AUTOSAR XML (schema 4-3-0)
package /APS_Interface_ARPkg
  client server interface IF_HALIN_APS
    5 x operation:
      CSOP_ApsGetData
        22 x arg, all with direction=OUT, server-argument-impl-policy=USE-ARGUMENT-TYPE:
          u8_GetAPS_Progress_PCT: type=uint8
          u8_GetAPS_RQ_Display: type=uint8
          u8_GetAPS_SW_Ver: type=uint8
          u8_GetAPS_HW_Ver: type=uint8
          u8_GetAPS_ExitCondition: type=uint8
          f32_GetAPS_Angle_Target: type=float32
          u8_GetAPS_Sta_System: type=uint8
          u8_GetAPS_V_Rq_EPAS_Ctrl: type=uint8
          u8_GetAPS_Rq_EPAS_Ctrl: type=uint8
          u8_GetAPS_Req: type=uint8
          f32_GetAPS_DecReq: type=float32
          u8_GetAPS_DecReq_A: type=uint8
          f32_GetAPS_SpeedCmd: type=float32
          u8_GetAPS_ShftPosnReq: type=uint8
          u8_GetAPS_VMC_Req_A: type=uint8
          u8_GetCAAS_Sta: type=uint8
          u8_GetCAAS_VMC_Req_A: type=uint8
          u8_GetAPS_PwrReq_cmd: type=uint8
          u8_GetRAPS_BCM_LockReq_Cmd: type=uint8
          u8_GetRAPS_BCM_Lamp_Cmd: type=uint8
          u8_GetRAPS_ErrWarn_Sta: type=uint8
          u8_GetRAPS_ErrLv1_flg: type=uint8
      CSOP_ApsGetDist
        arg u8Array8_PasInDist: type=u8_PASArray8_type, direction=OUT, server-argument-impl-policy=USE-ARGUMENT-TYPE
        arg u16Array4_ApsInDist: type=u16_APSArray4_type, direction=OUT, server-argument-impl-policy=USE-ARGUMENT-TYPE
      CSOP_ApsGetDistLevel
        arg u8Array8_ApsInLevel: type=u8_APSLevelArray8_type, direction=OUT, server-argument-impl-policy=USE-ARGUMENT-TYPE
      CSOP_ApsGetOtherStatus
        4 x arg, all with type=uint8, direction=OUT, server-argument-impl-policy=USE-ARGUMENT-TYPE:
          u8_ApsInPASChime
          u8_ApsInSensorLayout
          u8_ApsInSysFailSta
          u8_ApsInSysMode
      CSOP_ApsGetUssSta
        arg u8Array12_ApsInUssSta: type=u8_USSArray12_type, direction=OUT, server-argument-impl-policy=USE-ARGUMENT-TYPE
  client server interface IF_HALOUT_APS
    operation CSOP_ApsOutput
      6 x arg, all with direction=IN, server-argument-impl-policy=USE-ARGUMENT-TYPE:
        f32_ApsOutVehSpdSig: type=float32
        u8_ApsOutGearPosnSig: type=uint8
        u8_ApsOutSetFrSensorOnCmd: type=uint8
        u8_ApsOutSetVehSpdTOCmd: type=uint8
        u8_ApsOutSetFrSensorSwTOCmd: type=uint8
        u8_ApsOutSendChrgPlugSta: type=uint8
    operation CSOP_ApsSetData
      83 x arg, all with direction=IN, server-argument-impl-policy=USE-ARGUMENT-TYPE:
        u8_SetPwrSta: type=uint8
        f32_SetBrkPedalPos: type=float32
        f32_SetActAPSPosn: type=float32
        f32_SetLF_RawWhlSpeed: type=float32
        f32_SetRF_RawWhlSpeed: type=float32
        f32_SetLR_RawWhlSpeed: type=float32
        f32_SetRR_RawWhlSpeed: type=float32
        u8_SetLF_RawWhlSpeed_V: type=uint8
        u8_SetRF_RawWhlSpeed_V: type=uint8
        u8_SetLR_RawWhlSpeed_V: type=uint8
        u8_SetRR_RawWhlSpeed_V: type=uint8
        u8_SetLF_WhlRotDir: type=uint8
        u8_SetRF_WhlRotDir: type=uint8
        u8_SetLR_WhlRotDir: type=uint8
        u8_SetRR_WhlRotDir: type=uint8
        u8_SetLF_PulseCount_V: type=uint8
        u8_SetRF_PulseCount_V: type=uint8
        u8_SetLR_PulseCount_V: type=uint8
        u8_SetRR_PulseCount_V: type=uint8
        s16_SetLF_PulseCount: type=sint16
        s16_SetRF_PulseCount: type=sint16
        s16_SetLR_PulseCount: type=sint16
        s16_SetRR_PulseCount: type=sint16
        u8_SetAPS_Active: type=uint8
        u8_SetAPS_CtrlAvail: type=uint8
        u8_SetShifter_Handle_Cmd: type=uint8
        u8_SetDriIntend: type=uint8
        u8_SetEPS_AOI_Control: type=uint8
        f32_SetSAS_Angle: type=float32
        f32_SetSAS_Speed: type=float32
        u8_SetSAS_Speed_Valid: type=uint8
        u8_SetSAS_CAL: type=uint8
        u8_SetSAS_OK: type=uint8
        f32_SetGRADE: type=float32
        f32_SetYawRate: type=float32
        f32_SetLatAccel: type=float32
        f32_SetLongAccel: type=float32
        f32_SetMCPressure: type=float32
        u8_SetYawRate_V: type=uint8
        u8_SetLatAccel_V: type=uint8
        u8_SetLongAccel_V: type=uint8
        u8_SetMCPressure_V: type=uint8
        u8_SetBrkSw_Sta: type=uint8
        u8_SetBrkSw_V: type=uint8
        u8_SetESC_Standstill: type=uint8
        u8_SetESC_APS_Sta: type=uint8
        u8_SetEPBExtReleaseAvail: type=uint8
        u8_SetEPBExtApplyAvail: type=uint8
        u8_SetEPBErrSta: type=uint8
        u8_SetEPBSta: type=uint8
        u8_SetAllDoorSW: type=uint8
        u8_SetHoodSW: type=uint8
        u8_SetTailgate_SW: type=uint8
        u8_SetAVM_parking_cancel: type=uint8
        u8_SetAVM_parking_excute: type=uint8
        u8_SetAVM_Parking_mode: type=uint8
        u8_SetAVM_Err_STA: type=uint8
        u8_SetIVI_Status: type=uint8
        u8_SetCAAS_Sw: type=uint8
        u8_SetIVI_Screen: type=uint8
        u8_SetCAAS_CtrlAvail: type=uint8
        u8_SetABS_Active: type=uint8
        u8_SetTCS_Active: type=uint8
        u8_SetDriverSeatBeltCmd: type=uint8
        u8_SetDrDoorSW: type=uint8
        u8_SetPsDoorSW: type=uint8
        u8_SetRLDoorSW: type=uint8
        u8_SetRRDoorSW: type=uint8
        u8_SetRFPressIndi: type=uint8
        u8_SetLFPressIndi: type=uint8
        u8_SetRRPressIndi: type=uint8
        u8_SetLRPressIndi: type=uint8
        f32_SetsigAmbAirT: type=float32
        f32_SetVehActSpd: type=float32
        u8_SetCAAS_Active: type=uint8
        u8_SetAPS_PwrReqAvail_sta: type=uint8
        u8_SetDKC_PDkeyAreaRAPS_Sta: type=uint8
        u8_SetDKC_ParkingMode_Cmd: type=uint8
        u8_SetP_UID_LowPower: type=uint8
        u8_SetDr_SeatSta: type=uint8
        u8_SetVCU_RAPSErrLv2_flg: type=uint8
        u8_SetVCU_RAPSErrLv3_flg: type=uint8
        u8_SetIVI_UserTakeOver_APS_Sta: type=uint8
    operation CSOP_ApsSetTimeout
      69 x arg, all with type=uint8, direction=IN, server-argument-impl-policy=USE-ARGUMENT-TYPE:
        u8_SetBrkPedalPosTO
        u8_SetLF_RawWhlSpeedTO
        u8_SetRF_RawWhlSpeedTO
        u8_SetLR_RawWhlSpeedTO
        u8_SetRR_RawWhlSpeedTO
        u8_SetLF_RawWhlSpeed_VTO
        u8_SetRF_RawWhlSpeed_VTO
        u8_SetLR_RawWhlSpeed_VTO
        u8_SetRR_RawWhlSpeed_VTO
        u8_SetLF_WhlRotDirTO
        u8_SetRF_WhlRotDirTO
        u8_SetLR_WhlRotDirTO
        u8_SetRR_WhlRotDirTO
        u8_SetLF_PulseCount_VTO
        u8_SetRF_PulseCount_VTO
        u8_SetLR_PulseCount_VTO
        u8_SetRR_PulseCount_VTO
        u8_SetLF_PulseCountTO
        u8_SetRF_PulseCountTO
        u8_SetLR_PulseCountTO
        u8_SetRR_PulseCountTO
        u8_SetShifter_Handle_CmdTO
        u8_SetDriIntendTO
        u8_SetEPS_AOI_ControlTO
        u8_SetSAS_AngleTO
        u8_SetSAS_SpeedTO
        u8_SetSAS_Speed_ValidTO
        u8_SetSAS_CALTO
        u8_SetSAS_OKTO
        u8_SetGRADETO
        u8_SetYawRateTO
        u8_SetLatAccelTO
        u8_SetLongAccelTO
        u8_SetMCPressureTO
        u8_SetYawRate_VTO
        u8_SetLatAccel_VTO
        u8_SetLongAccel_VTO
        u8_SetMCPressure_VTO
        u8_SetBrkSw_StaTO
        u8_SetBrkSw_VTO
        u8_SetESC_StandstillTO
        u8_SetESC_APS_StaTO
        u8_SetEPBExtReleaseAvailTO
        u8_SetEPBExtApplyAvailTO
        u8_SetEPBErrStaTO
        u8_SetEPBStaTO
        u8_SetAVM_parking_cancelTO
        u8_SetAVM_parking_excuteTO
        u8_SetAVM_Parking_modeTO
        u8_SetAVM_Err_STATO
        u8_SetIVI_StatusTO
        u8_SetCAAS_SwTO
        u8_SetIVI_ScreenTO
        u8_SetABS_ActiveTO
        u8_SetTCS_ActiveTO
        u8_SetDriverSeatBeltCmdTO
        u8_SetRFPressIndiTO
        u8_SetLFPressIndiTO
        u8_SetRRPressIndiTO
        u8_SetLRPressIndiTO
        u8_SetsigAmbAirTTO
        u8_SetAPS_PwrReqAvail_staTO
        u8_SetDKC_PDkeyAreaRAPS_StaTO
        u8_SetDKC_ParkingMode_CmdTO
        u8_SetP_UID_LowPowerTO
        u8_SetDr_SeatStaTO
        u8_SetVCU_RAPSErrLv2_flgTO
        u8_SetVCU_RAPSErrLv3_flgTO
        u8_SetIVI_UserTakeOver_APS_StaTO
package /Impl_SWC_APS_ARPkg
  swc implementation Impl_SWC_APS_type: programming-language=C, sw-version=1.0.0, vendor-id=0, behavior=SWC_APS_type_IB
    code-descriptors:
      code SRC: artifact-descriptors=autosar-engineering-object={short-label=EngObject, category=SWSRC}
    resource consumption ResourceConsumption
      memory section Mem_SWC_APS_CODE: size=0, sw-addrmethod=CODE, symbol=CODE
package /Impl_Type_ARPkg
  4 x impl type, all with category=ARRAY:
    u16_APSArray4_type
      element u16_ApsElement: category=VALUE, array-size=4, array-size-semantics=FIXED-SIZE, base-type=uint16
    u8_APSLevelArray8_type
      element u8_APSLevelElement: category=VALUE, array-size=8, array-size-semantics=FIXED-SIZE, base-type=uint8
    u8_PASArray8_type
      element u8_PasElement: category=VALUE, array-size=8, array-size-semantics=FIXED-SIZE, base-type=uint8
    u8_USSArray12_type
      element u8_UssElement: category=VALUE, array-size=12, array-size-semantics=FIXED-SIZE, base-type=uint8
package /SWC_APS_ARPkg
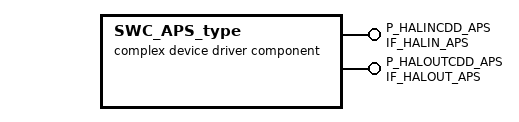
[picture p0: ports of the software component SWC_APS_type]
  complex device driver sw component type SWC_APS_type
    provide port P_HALINCDD_APS: provided-interface=IF_HALIN_APS
    provide port P_HALOUTCDD_APS: provided-interface=IF_HALOUT_APS
    behavior SWC_APS_type_IB: handle-termination-and-restart=NO-SUPPORT
      8 x operation invoked event:
        oie_P_HALINCDD_APS_CSOP_ApsGetData: start-on-event=run_HALINAPS_ApsGetData, operation=P_HALINCDD_APS.CSOP_ApsGetData
        oie_P_HALINCDD_APS_CSOP_ApsGetDist: start-on-event=run_HALINAPS_ApsGetDist, operation=P_HALINCDD_APS.CSOP_ApsGetDist
        oie_P_HALINCDD_APS_CSOP_ApsGetDistLevel: start-on-event=run_HALINAPS_ApsGetDistLevel, operation=P_HALINCDD_APS.CSOP_ApsGetDistLevel
        oie_P_HALINCDD_APS_CSOP_ApsGetOtherStatus: start-on-event=run_HALINAPS_GetApsOtherStatus, operation=P_HALINCDD_APS.CSOP_ApsGetOtherStatus
        oie_P_HALINCDD_APS_CSOP_ApsGetUssSta: start-on-event=run_HALINAPS_ApsGetUssSta, operation=P_HALINCDD_APS.CSOP_ApsGetUssSta
        oie_P_HALOUTCDD_APS_CSOP_ApsOutput: start-on-event=run_HALOUTAPS_ApsOutput, operation=P_HALOUTCDD_APS.CSOP_ApsOutput
        oie_P_HALOUTCDD_APS_CSOP_ApsSetData: start-on-event=run_HALOUTAPS_ApsSetData, operation=P_HALOUTCDD_APS.CSOP_ApsSetData
        oie_P_HALOUTCDD_APS_CSOP_ApsSetTimeout: start-on-event=run_HALOUTAPS_ApsSetTimeout, operation=P_HALOUTCDD_APS.CSOP_ApsSetTimeout
      port-api-options:
        enable-take-address=false, indirect-api=false, port=P_HALINCDD_APS
        enable-take-address=false, indirect-api=false, port=P_HALOUTCDD_APS
      8 x runnable:
        run_HALINAPS_ApsGetData
        run_HALINAPS_ApsGetDist
        run_HALINAPS_ApsGetDistLevel
        run_HALINAPS_ApsGetUssSta
        run_HALINAPS_GetApsOtherStatus
        run_HALOUTAPS_ApsOutput
        run_HALOUTAPS_ApsSetData
        run_HALOUTAPS_ApsSetTimeout
